# MCU_FSS0_OSPI0_SS_CFG register map
Vendor: Texas Instruments
Peripheral module from a debugger description file (folder am65x).
Registers are 32-bit, read-only, reset values left out (the file's numbers can be read two ways) unless marked. A register's access mark holds for its fields unless they carry their own. Offsets are as the file gives them; lines under a group give offsets from that group; [hi:lo] are bit positions; {n}, {i} and the like mark numbered series; 'fields as' and 'values as' point back to an identical list; <NAME> marks a mode.

## MCU_FSS0_OSPI0_SS_CFG
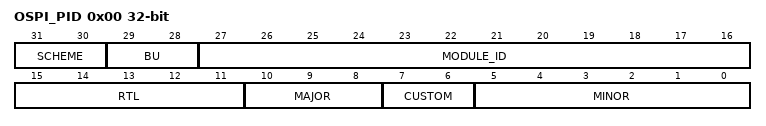
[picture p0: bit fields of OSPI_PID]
0x00 OSPI_PID — The Revision Register contains the major and minor revisions for the module.
  [31:30] SCHEME
  [29:28] BU — Business Unit:10 = Processors
  [27:16] MODULE_ID
  [15:11] RTL — RTL revision. Will vary depending on release.Bit field reset value:SR2.0: ChSR1.0: 8h
  [10:8] MAJOR — Major revision
  [7:6] CUSTOM
  [5:0] MINOR — Minor revision
0x04 OSPI_CTRL rw — The Control Register contains general control bits for the OSPI.
  [3] PIPELINE_MODE_FLUSH — 1h = Flush Flash Controller FIFO by forcing data interface slave select signal low. 0h = Data interface slave select signal to Controller is 1.
0x08 OSPI_STAT — The Status register provide general status bits for the OSPI.
  [1] MEM_INIT_DONE — 0h = Memory initialization is in progress, 1h = Memory intialization is done.
0x20 OSPI_EOI wo — End of Interrupt Register The EOI register is used to re-trigger the pulse interrupt signal to ensure that any nested interrupt events are serviced. The software interrupt handler must write to the EOI register at the end of the current interrupt processing routine, so that new events can re-trigger the pulse interrupt signal again. For level interrupt signals the EOI register is not functional and must not be used. Some of the OSPI features described in this section may not be supported on this family of devices. For more information, see , OSPI Not Supported Features.
  [7:0] EOI — Write with bit position of targetted interrupt.(that is Ext TS is bit 0). Upon write, level interrupt will clear and if unserviced interrupt counter &gt; 1 will issue another pulse interrupt.
